VERSION ""

NS_ :

BS_:

BU_: XXX BCM CEM FSM PSCM SAS

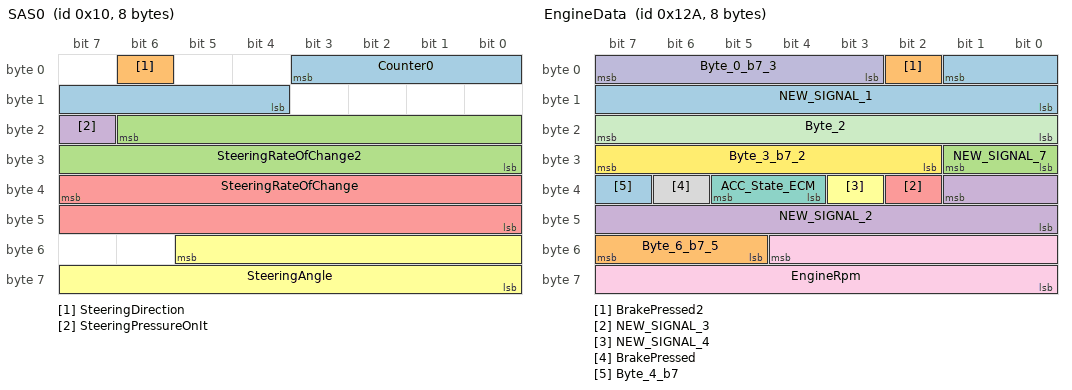
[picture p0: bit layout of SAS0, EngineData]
BO_ 16 SAS0: 8 SAS
 SG_ Counter0 : 3|8@0+ (1,0) [0|511] "" XXX
 SG_ SteeringDirection : 6|1@0+ (1,0) [0|1] "" XXX
 SG_ SteeringRateOfChange2 : 22|15@0+ (1,0) [0|32767] "" XXX
 SG_ SteeringPressureOnIt : 23|1@0+ (1,0) [0|1] "" XXX
 SG_ SteeringRateOfChange : 39|16@0+ (1,-32768) [0|65535] "" XXX
 SG_ SteeringAngle : 53|14@0+ (0.0445,0) [0|65535] "degrees" XXX

BO_ 32 AccPedal: 8 XXX
 SG_ AccPedal : 17|10@0+ (0.1,0) [0|102.3] "%" XXX

BO_ 81 FSM0: 8 FSM
 SG_ ACC_FrontCar : 16|1@0+ (1,0) [0|1] "" XXX
 SG_ ACC_Available : 17|1@0+ (1,0) [0|7] "" XXX
 SG_ ACC_Enabled : 18|1@0+ (1,0) [0|1] "" XXX
 SG_ ACC_BrakeAlert : 27|1@0+ (1,0) [0|1] "" XXX
 SG_ Byte_0 : 7|8@0+ (1,0) [0|255] "" XXX
 SG_ Byte_1 : 15|8@0+ (1,0) [0|255] "" XXX
 SG_ Byte_2_b7_3 : 23|5@0+ (1,0) [0|31] "" XXX
 SG_ ACC_AbortCode : 31|8@0+ (1,0) [0|255] "" XXX
 SG_ Byte_4 : 39|8@0+ (1,0) [0|255] "" XXX
 SG_ Byte_5 : 47|8@0+ (1,0) [0|255] "" XXX
 SG_ Byte_6 : 55|8@0+ (1,0) [0|255] "" XXX
 SG_ Byte_7 : 63|8@0+ (1,0) [0|255] "" XXX

BO_ 99 GearSelector: 8 XXX
 SG_ GearLever : 54|2@0+ (1,0) [0|3] "" XXX

BO_ 112 ButtonPanel: 8 XXX
 SG_ Console_Button_Pressed : 18|1@0+ (1,0) [0|1] "" XXX

BO_ 277 NEW_MSG_7: 8 XXX
 SG_ NEW_SIGNAL_1 : 39|16@0+ (1,0) [0|65535] "" XXX

BO_ 295 CCButtons: 8 CEM
 SG_ ACCMinusBtnInv : 32|1@0+ (1,0) [0|1] "" XXX
 SG_ TimeGapIncreaseBtnInv : 33|1@0+ (1,0) [0|1] "" XXX
 SG_ TimeGapDecreaseBtnInv : 34|1@0+ (1,0) [0|1] "" XXX
 SG_ ACCOnOffBtnInv : 43|1@0+ (1,0) [0|1] "" XXX
 SG_ ACCResumeBtnInv : 45|1@0+ (1,0) [0|1] "" XXX
 SG_ ACCSetBtnInv : 47|1@0+ (1,0) [0|1] "" XXX
 SG_ ACCMinusBtn : 48|1@0+ (1,0) [0|1] "" XXX
 SG_ TimeGapIncreaseBtn : 49|1@0+ (1,0) [0|1] "" XXX
 SG_ TimeGapDecreaseBtn : 50|1@0+ (1,0) [0|1] "" XXX
 SG_ ACCOnOffBtn : 59|1@0+ (1,0) [0|1] "" XXX
 SG_ ACCResumeBtn : 61|1@0+ (1,0) [0|1] "" XXX
 SG_ ACCSetBtn : 63|1@0+ (1,0) [0|1] "" XXX
 SG_ Byte_0 : 7|8@0+ (1,0) [0|255] "" XXX
 SG_ Byte_1 : 15|8@0+ (1,0) [0|255] "" XXX
 SG_ Byte_2_b7_3 : 23|5@0+ (1,0) [0|31] "" XXX
 SG_ LKA_State : 18|1@0+ (1,0) [0|1] "" XXX
 SG_ Byte_2_b1_0 : 17|2@0+ (1,0) [0|3] "" XXX
 SG_ Byte_3 : 31|8@0+ (1,0) [0|255] "" XXX
 SG_ Byte_4_b7_3 : 39|5@0+ (1,0) [0|31] "" XXX
 SG_ Byte_5_b6 : 46|1@0+ (1,0) [0|1] "" XXX
 SG_ Byte_5_b4 : 44|1@0+ (1,0) [0|1] "" XXX
 SG_ Byte_5_b2_0 : 42|3@0+ (1,0) [0|7] "" XXX
 SG_ Byte_6_b7_3 : 55|5@0+ (1,0) [0|31] "" XXX
 SG_ Byte_7_b6 : 62|1@0+ (1,0) [0|1] "" XXX
 SG_ Byte_7_b4 : 60|1@0+ (1,0) [0|1] "" XXX
 SG_ Byte_7_b2_0 : 58|3@0+ (1,0) [0|7] "" XXX

BO_ 298 EngineData: 8 XXX
 SG_ NEW_SIGNAL_1 : 1|10@0+ (1,0) [0|1023] "" XXX
 SG_ BrakePressed2 : 2|1@0+ (1,0) [0|1] "" XXX
 SG_ NEW_SIGNAL_7 : 25|2@0+ (1,0) [0|3] "" XXX
 SG_ NEW_SIGNAL_2 : 33|10@0- (1,0) [0|7] "" XXX
 SG_ NEW_SIGNAL_3 : 34|1@0+ (1,0) [0|1] "" XXX
 SG_ NEW_SIGNAL_4 : 35|1@0+ (1,0) [0|1] "" XXX
 SG_ ACC_State_ECM : 37|2@0+ (1,0) [0|3] "" XXX
 SG_ BrakePressed : 38|1@0+ (1,0) [0|1] "" XXX
 SG_ EngineRpm : 52|13@0+ (1,0) [0|8000] "" XXX
 SG_ Byte_0_b7_3 : 7|5@0+ (1,0) [0|31] "" XXX
 SG_ Byte_2 : 23|8@0+ (1,0) [0|255] "" XXX
 SG_ Byte_3_b7_2 : 31|6@0+ (1,0) [0|63] "" XXX
 SG_ Byte_4_b7 : 39|1@0+ (1,0) [0|1] "" XXX
 SG_ Byte_6_b7_5 : 55|3@0+ (1,0) [0|7] "" XXX

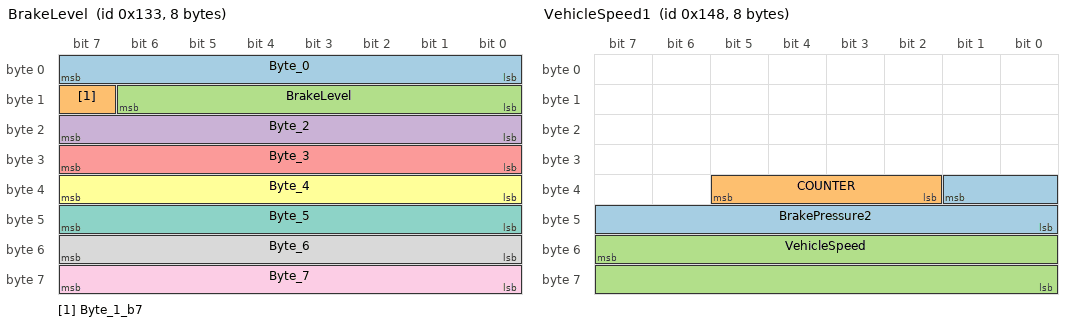
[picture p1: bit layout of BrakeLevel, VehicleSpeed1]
BO_ 307 BrakeLevel: 8 XXX
 SG_ Byte_0 : 7|8@0+ (1,0) [0|255] "" XXX
 SG_ Byte_1_b7 : 15|1@0+ (1,0) [0|1] "" XXX
 SG_ BrakeLevel : 14|7@0+ (1,0) [0|127] "" XXX
 SG_ Byte_2 : 23|8@0+ (1,0) [0|255] "" XXX
 SG_ Byte_3 : 31|8@0+ (1,0) [0|255] "" XXX
 SG_ Byte_4 : 39|8@0+ (1,0) [0|255] "" XXX
 SG_ Byte_5 : 47|8@0+ (1,0) [0|255] "" XXX
 SG_ Byte_6 : 55|8@0+ (1,0) [0|255] "" XXX
 SG_ Byte_7 : 63|8@0+ (1,0) [0|255] "" XXX

BO_ 328 VehicleSpeed1: 8 XXX
 SG_ BrakePressure2 : 33|10@0+ (1,0) [0|63] "" XXX
 SG_ COUNTER : 37|4@0+ (1,0) [0|15] "" XXX
 SG_ VehicleSpeed : 55|16@0+ (0.01,0) [0|65535] "" XXX

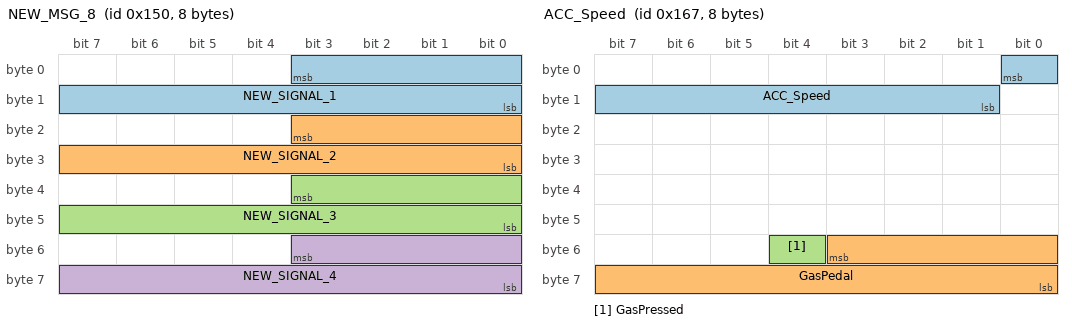
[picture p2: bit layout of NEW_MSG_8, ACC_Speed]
BO_ 336 NEW_MSG_8: 8 XXX
 SG_ NEW_SIGNAL_1 : 3|12@0+ (1,0) [0|4095] "" XXX
 SG_ NEW_SIGNAL_2 : 19|12@0+ (1,0) [0|4095] "" XXX
 SG_ NEW_SIGNAL_3 : 35|12@0+ (1,0) [0|4095] "" XXX
 SG_ NEW_SIGNAL_4 : 51|12@0+ (1,0) [0|4095] "" XXX

BO_ 359 ACC_Speed: 8 XXX
 SG_ ACC_Speed : 0|8@0+ (1,0) [0|255] "km/h" XXX
 SG_ GasPedal : 51|12@0- (1,0) [0|255] "" XXX
 SG_ GasPressed : 52|1@0+ (1,0) [0|1] "" XXX

BO_ 384 Accessories_02: 8 XXX
 SG_ Park_Assist_State : 42|1@0+ (1,0) [0|1] "" XXX
 SG_ StartStop_Inv : 44|1@0+ (1,0) [0|1] "" XXX

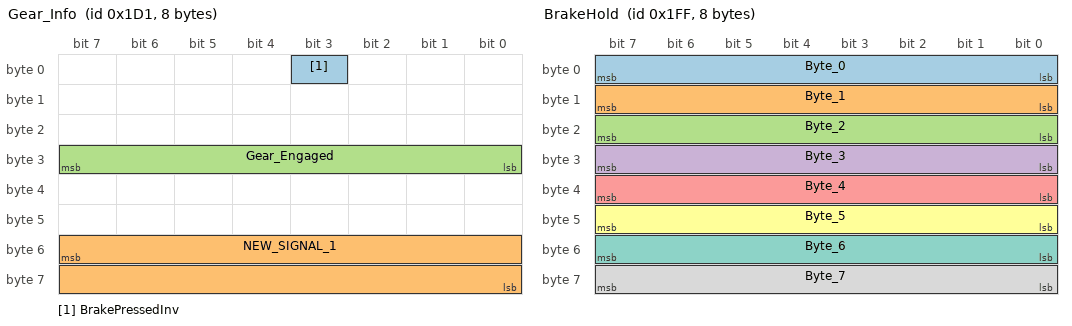
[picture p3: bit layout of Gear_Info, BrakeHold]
BO_ 465 Gear_Info: 8 XXX
 SG_ BrakePressedInv : 3|1@0+ (1,0) [0|1] "" XXX
 SG_ NEW_SIGNAL_1 : 55|16@0+ (1,0) [0|4095] "" XXX
 SG_ Gear_Engaged : 31|8@0+ (1,0) [0|255] "" XXX

BO_ 511 BrakeHold: 8 XXX
 SG_ Byte_0 : 7|8@0+ (1,0) [0|255] "" XXX
 SG_ Byte_1 : 15|8@0+ (1,0) [0|255] "" XXX
 SG_ Byte_2 : 23|8@0+ (1,0) [0|255] "" XXX
 SG_ Byte_3 : 31|8@0+ (1,0) [0|255] "" XXX
 SG_ Byte_4 : 39|8@0+ (1,0) [0|255] "" XXX
 SG_ Byte_5 : 47|8@0+ (1,0) [0|255] "" XXX
 SG_ Byte_6 : 55|8@0+ (1,0) [0|255] "" XXX
 SG_ Byte_7 : 63|8@0+ (1,0) [0|255] "" XXX

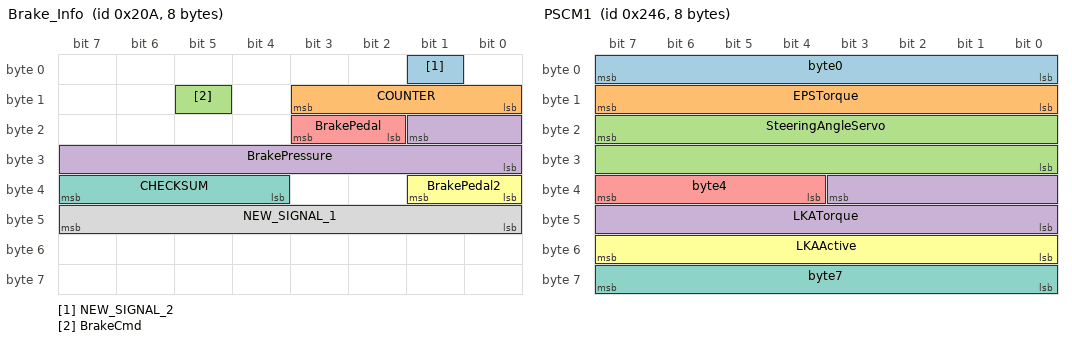
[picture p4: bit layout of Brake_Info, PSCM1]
BO_ 522 Brake_Info: 8 XXX
 SG_ NEW_SIGNAL_2 : 1|1@0+ (1,0) [0|1] "" XXX
 SG_ COUNTER : 11|4@0+ (1,0) [0|15] "" XXX
 SG_ BrakeCmd : 13|1@0+ (1,0) [0|1] "" XXX
 SG_ BrakePressure : 17|10@0+ (1,0) [0|255] "" XXX
 SG_ BrakePedal : 19|2@0+ (1,0) [0|3] "" XXX
 SG_ BrakePedal2 : 33|2@0+ (1,0) [0|3] "" XXX
 SG_ CHECKSUM : 39|4@0+ (1,0) [0|15] "" XXX
 SG_ NEW_SIGNAL_1 : 47|8@0+ (1,0) [0|255] "" XXX

BO_ 544 wheelspeed1: 8 BCM
 SG_ WhlSpdRR : 39|16@0+ (0.01,-327.68) [0|65535] "" XXX
 SG_ WhlSpdLR : 55|16@0+ (0.01,-327.68) [0|65535] "" XXX
 SG_ Byte_0_b7 : 7|1@0+ (1,0) [0|1] "" XXX
 SG_ StandstillHold : 6|1@0+ (1,0) [0|1] "" XXX
 SG_ Byte_0_b5_0 : 5|6@0+ (1,0) [0|63] "" XXX
 SG_ Byte_1 : 15|8@0+ (1,0) [0|255] "" XXX
 SG_ Byte_2_b7_3 : 23|5@0+ (1,0) [0|31] "" XXX
 SG_ BrakeReqActive : 18|1@0+ (1,0) [0|1] "" XXX
 SG_ Byte_2_b1 : 17|1@0+ (1,0) [0|1] "" XXX
 SG_ ACC_BrakeApplied : 16|1@0+ (1,0) [0|1] "" XXX
 SG_ Byte_3 : 31|8@0+ (1,0) [0|255] "" XXX
 SG_ Byte_4 : 39|8@0+ (1,0) [0|255] "" XXX
 SG_ Byte_5 : 47|8@0+ (1,0) [0|255] "" XXX
 SG_ Byte_6 : 55|8@0+ (1,0) [0|255] "" XXX
 SG_ Byte_7 : 63|8@0+ (1,0) [0|255] "" XXX

BO_ 565 wheelspeed0: 8 BCM
 SG_ WhlSpdRF : 39|16@0+ (0.01,-327.68) [0|65535] "" XXX
 SG_ WhlSpdLF : 55|16@0+ (0.01,-327.68) [0|65535] "" XXX

BO_ 582 PSCM1: 8 PSCM
 SG_ byte0 : 7|8@0+ (1,0) [0|255] "" XXX
 SG_ EPSTorque : 15|8@0+ (1,0) [0|255] "" XXX
 SG_ SteeringAngleServo : 23|16@0+ (0.0447,-1465) [0|65535] "deg" XXX
 SG_ LKATorque : 35|12@0+ (1,-2000) [0|65535] "" XXX
 SG_ byte4 : 39|4@0+ (1,0) [0|15] "" XXX
 SG_ LKAActive : 55|8@0+ (1,0) [0|255] "" XXX
 SG_ byte7 : 63|8@0+ (1,0) [0|255] "" XXX

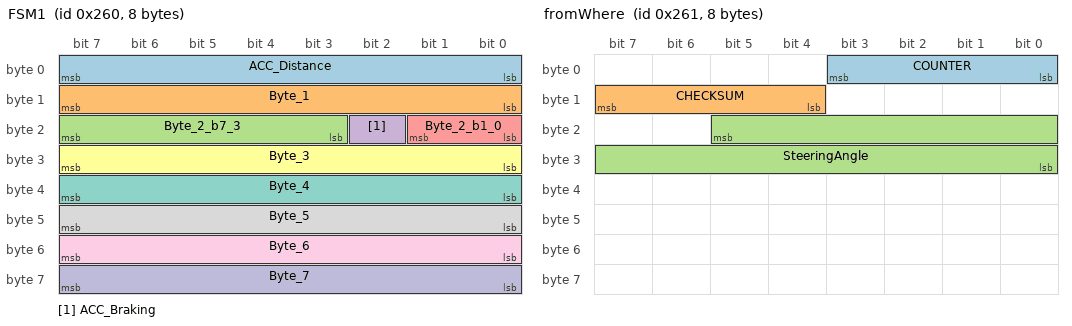
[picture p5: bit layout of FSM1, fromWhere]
BO_ 608 FSM1: 8 FSM
 SG_ ACC_Distance : 7|8@0+ (1,0) [0|255] "" XXX
 SG_ Byte_1 : 15|8@0+ (1,0) [0|255] "" XXX
 SG_ Byte_2_b7_3 : 23|5@0+ (1,0) [0|31] "" XXX
 SG_ ACC_Braking : 18|1@0+ (1,0) [0|1] "" XXX
 SG_ Byte_2_b1_0 : 17|2@0+ (1,0) [0|3] "" XXX
 SG_ Byte_3 : 31|8@0+ (1,0) [0|255] "" XXX
 SG_ Byte_4 : 39|8@0+ (1,0) [0|255] "" XXX
 SG_ Byte_5 : 47|8@0+ (1,0) [0|255] "" XXX
 SG_ Byte_6 : 55|8@0+ (1,0) [0|255] "" XXX
 SG_ Byte_7 : 63|8@0+ (1,0) [0|255] "" XXX

BO_ 609 fromWhere: 8 XXX
 SG_ COUNTER : 3|4@0+ (1,0) [0|15] "" XXX
 SG_ CHECKSUM : 15|4@0+ (1,0) [0|15] "" XXX
 SG_ SteeringAngle : 21|14@0+ (0.1,-1021) [0|65535] "deg" XXX

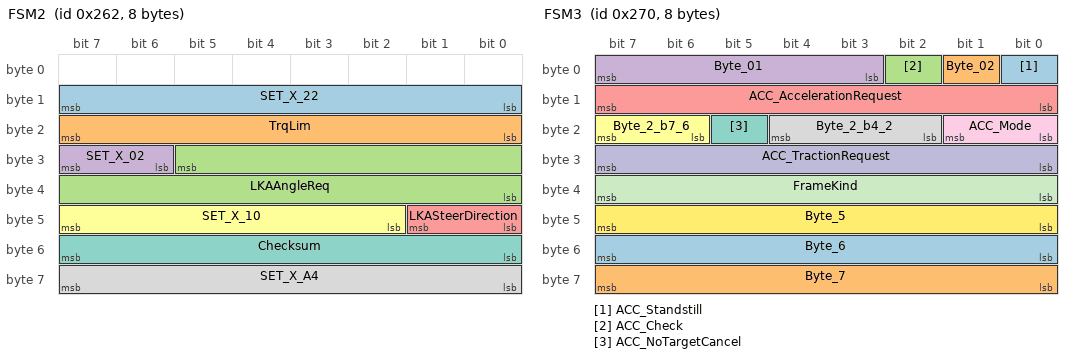
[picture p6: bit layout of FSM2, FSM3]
BO_ 610 FSM2: 8 FSM
 SG_ SET_X_22 : 15|8@0+ (1,0) [0|255] "" XXX
 SG_ TrqLim : 23|8@0+ (1,-128) [0|255] "" PSCM
 SG_ LKAAngleReq : 29|14@0+ (0.04,-327.68) [0|16383] "" PSCM
 SG_ SET_X_02 : 31|2@0+ (1,0) [0|3] "" XXX
 SG_ LKASteerDirection : 41|2@0+ (1,0) [0|3] "" PSCM
 SG_ SET_X_10 : 47|6@0+ (1,0) [0|63] "" XXX
 SG_ Checksum : 55|8@0+ (1,0) [0|255] "" PSCM
 SG_ SET_X_A4 : 63|8@0+ (1,0) [0|255] "" XXX

BO_ 612 Accessories_03: 8 XXX
 SG_ Park_Assist_Button : 60|1@0+ (1,0) [0|1] "" XXX
 SG_ RearParkWarning_Button : 58|1@0+ (1,0) [0|1] "" XXX

BO_ 624 FSM3: 8 FSM
 SG_ ACC_Standstill : 0|1@0+ (1,0) [0|1] "" XXX
 SG_ Byte_02 : 1|1@0+ (1,0) [0|1] "" XXX
 SG_ ACC_Check : 2|1@0+ (1,0) [0|1] "" XXX
 SG_ Byte_01 : 7|5@0+ (1,0) [0|31] "" XXX
 SG_ ACC_AccelerationRequest : 15|8@0+ (0.04,-5.04) [0|255] "" XXX
 SG_ Byte_2_b7_6 : 23|2@0+ (1,0) [0|3] "" XXX
 SG_ ACC_NoTargetCancel : 21|1@0+ (1,0) [0|1] "" XXX
 SG_ Byte_2_b4_2 : 20|3@0+ (1,0) [0|7] "" XXX
 SG_ ACC_Mode : 17|2@0+ (1,0) [0|3] "" XXX
 SG_ ACC_TractionRequest : 31|8@0+ (1,0) [0|255] "" XXX
 SG_ FrameKind : 39|8@0+ (1,0) [0|255] "" XXX
 SG_ Byte_5 : 47|8@0+ (1,0) [0|255] "" XXX
 SG_ Byte_6 : 55|8@0+ (1,0) [0|255] "" XXX
 SG_ Byte_7 : 63|8@0+ (1,0) [0|255] "" XXX

BO_ 648 BrakePedal: 8 XXX
 SG_ Counter : 0|3@1+ (1,0) [0|6] "" XXX
 SG_ BrakePressure : 17|10@0+ (1,0) [0|1023] "" XXX

BO_ 750 HandBrake: 8 XXX
 SG_ Hand_Brake_Button : 33|2@0+ (1,0) [0|3] "" XXX
 SG_ Hand_Brake_State : 44|4@0+ (1,0) [0|15] "" XXX

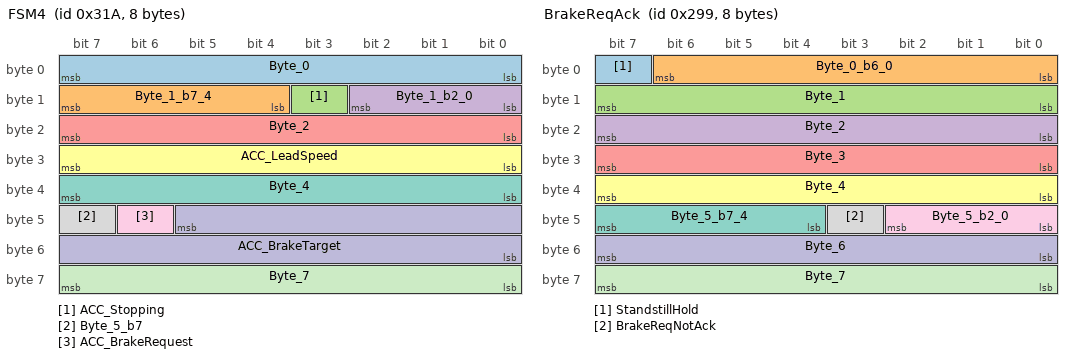
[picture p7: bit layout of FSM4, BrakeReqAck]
BO_ 794 FSM4: 8 FSM
 SG_ Byte_0 : 7|8@0+ (1,0) [0|255] "" XXX
 SG_ Byte_1_b7_4 : 15|4@0+ (1,0) [0|15] "" XXX
 SG_ ACC_Stopping : 11|1@0+ (1,0) [0|1] "" XXX
 SG_ Byte_1_b2_0 : 10|3@0+ (1,0) [0|7] "" XXX
 SG_ Byte_2 : 23|8@0+ (1,0) [0|255] "" XXX
 SG_ ACC_LeadSpeed : 31|8@0+ (1,0) [0|255] "" XXX
 SG_ Byte_4 : 39|8@0+ (1,0) [0|255] "" XXX
 SG_ Byte_5_b7 : 47|1@0+ (1,0) [0|1] "" XXX
 SG_ ACC_BrakeRequest : 46|1@0+ (1,0) [0|1] "" XXX
 SG_ ACC_BrakeTarget : 45|14@0+ (1,0) [0|16383] "" XXX
 SG_ Byte_7 : 63|8@0+ (1,0) [0|255] "" XXX

BO_ 665 BrakeReqAck: 8 XXX
 SG_ StandstillHold : 7|1@0+ (1,0) [0|1] "" XXX
 SG_ Byte_0_b6_0 : 6|7@0+ (1,0) [0|127] "" XXX
 SG_ Byte_1 : 15|8@0+ (1,0) [0|255] "" XXX
 SG_ Byte_2 : 23|8@0+ (1,0) [0|255] "" XXX
 SG_ Byte_3 : 31|8@0+ (1,0) [0|255] "" XXX
 SG_ Byte_4 : 39|8@0+ (1,0) [0|255] "" XXX
 SG_ Byte_5_b7_4 : 47|4@0+ (1,0) [0|15] "" XXX
 SG_ BrakeReqNotAck : 43|1@0+ (1,0) [0|1] "" XXX
 SG_ Byte_5_b2_0 : 42|3@0+ (1,0) [0|7] "" XXX
 SG_ Byte_6 : 55|8@0+ (1,0) [0|255] "" XXX
 SG_ Byte_7 : 63|8@0+ (1,0) [0|255] "" XXX

BO_ 706 RearParkWarning_Status: 8 XXX
 SG_ RearParkWarning_State : 35|1@0+ (1,0) [0|1] "" XXX

BO_ 807 ParkAssist_Status: 8 XXX
 SG_ Park_Assist_Off : 40|1@0+ (1,0) [0|1] "" XXX

BO_ 802 StartStop: 8 XXX
 SG_ StartStop : 8|1@0+ (1,0) [0|1] "" XXX

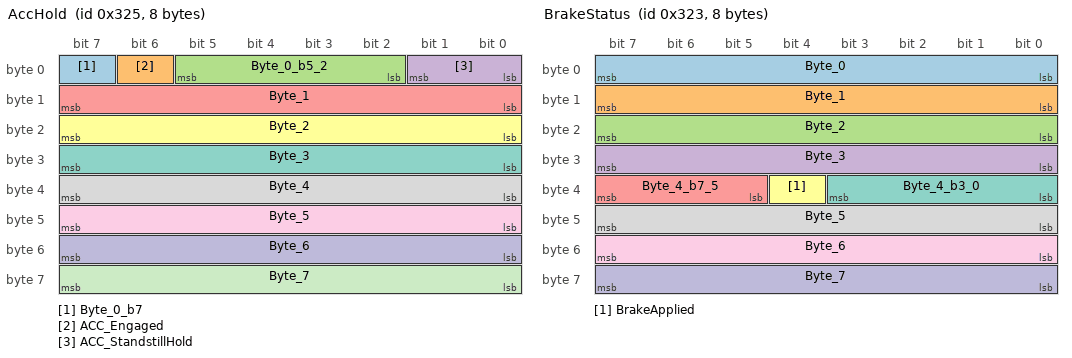
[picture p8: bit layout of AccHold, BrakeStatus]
BO_ 805 AccHold: 8 XXX
 SG_ Byte_0_b7 : 7|1@0+ (1,0) [0|1] "" XXX
 SG_ ACC_Engaged : 6|1@0+ (1,0) [0|1] "" XXX
 SG_ Byte_0_b5_2 : 5|4@0+ (1,0) [0|15] "" XXX
 SG_ ACC_StandstillHold : 1|2@0+ (1,0) [0|3] "" XXX
 SG_ Byte_1 : 15|8@0+ (1,0) [0|255] "" XXX
 SG_ Byte_2 : 23|8@0+ (1,0) [0|255] "" XXX
 SG_ Byte_3 : 31|8@0+ (1,0) [0|255] "" XXX
 SG_ Byte_4 : 39|8@0+ (1,0) [0|255] "" XXX
 SG_ Byte_5 : 47|8@0+ (1,0) [0|255] "" XXX
 SG_ Byte_6 : 55|8@0+ (1,0) [0|255] "" XXX
 SG_ Byte_7 : 63|8@0+ (1,0) [0|255] "" XXX

BO_ 803 BrakeStatus: 8 XXX
 SG_ Byte_0 : 7|8@0+ (1,0) [0|255] "" XXX
 SG_ Byte_1 : 15|8@0+ (1,0) [0|255] "" XXX
 SG_ Byte_2 : 23|8@0+ (1,0) [0|255] "" XXX
 SG_ Byte_3 : 31|8@0+ (1,0) [0|255] "" XXX
 SG_ Byte_4_b7_5 : 39|3@0+ (1,0) [0|7] "" XXX
 SG_ BrakeApplied : 36|1@0+ (1,0) [0|1] "" XXX
 SG_ Byte_4_b3_0 : 35|4@0+ (1,0) [0|15] "" XXX
 SG_ Byte_5 : 47|8@0+ (1,0) [0|255] "" XXX
 SG_ Byte_6 : 55|8@0+ (1,0) [0|255] "" XXX
 SG_ Byte_7 : 63|8@0+ (1,0) [0|255] "" XXX

BO_ 923 Accessories_01: 8 XXX
 SG_ NEW_SIGNAL_1 : 15|16@0+ (1,0) [0|65535] "" XXX
 SG_ Wipers : 38|2@0+ (1,0) [0|3] "" XXX

BO_ 1006 Doors: 8 XXX
 SG_ DriverDoorClosed : 8|1@0+ (1,0) [0|1] "" XXX
 SG_ PassengerDoorClosed : 9|1@0+ (1,0) [0|1] "" XXX

BO_ 1021 FSM5: 8 FSM
 SG_ TSR_Speed : 25|4@1+ (10,0) [0|15] "km/h" XXX

BO_ 1024 NEW_MSG_400: 8 XXX
 SG_ NEW_SIGNAL_1 : 25|8@0+ (1,0) [0|255] "" XXX

BO_ 1039 MiscCarInfo: 8 XXX
 SG_ TurnSignal : 33|2@0+ (1,0) [0|3] "" XXX

BO_ 1174 Lights: 8 XXX
 SG_ High_Beam : 23|1@0+ (1,0) [0|1] "" XXX

BO_ 1279 PSCM3: 8 PSCM

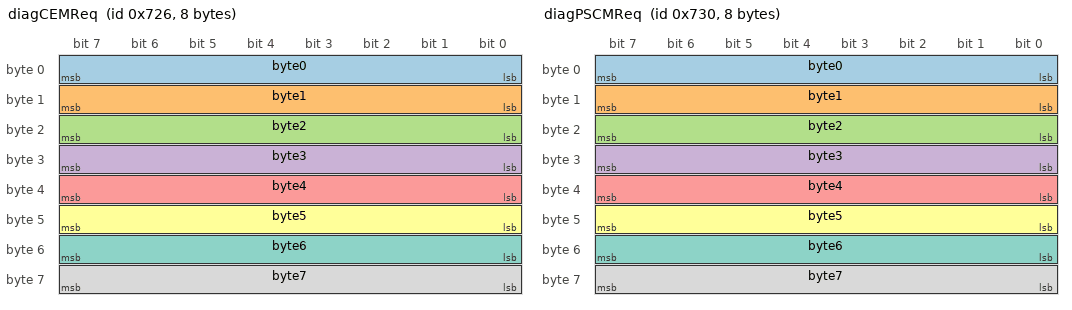
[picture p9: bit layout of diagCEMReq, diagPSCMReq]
BO_ 1830 diagCEMReq: 8 XXX
 SG_ byte0 : 7|8@0+ (1,0) [0|255] "" XXX
 SG_ byte1 : 15|8@0+ (1,0) [0|255] "" XXX
 SG_ byte2 : 23|8@0+ (1,0) [0|255] "" XXX
 SG_ byte3 : 31|8@0+ (1,0) [0|255] "" XXX
 SG_ byte4 : 39|8@0+ (1,0) [0|255] "" XXX
 SG_ byte5 : 47|8@0+ (1,0) [0|255] "" XXX
 SG_ byte6 : 55|8@0+ (1,0) [0|255] "" XXX
 SG_ byte7 : 63|8@0+ (1,0) [0|255] "" XXX

BO_ 1838 diagCEMResp: 8 XXX
 SG_ byte03 : 7|32@0+ (1,0) [0|4294967295] "" XXX
 SG_ byte47 : 39|32@0+ (1,0) [0|4294967295] "" XXX

BO_ 1840 diagPSCMReq: 8 XXX
 SG_ byte0 : 7|8@0+ (1,0) [0|255] "" XXX
 SG_ byte1 : 15|8@0+ (1,0) [0|255] "" XXX
 SG_ byte2 : 23|8@0+ (1,0) [0|255] "" XXX
 SG_ byte3 : 31|8@0+ (1,0) [0|255] "" XXX
 SG_ byte4 : 39|8@0+ (1,0) [0|255] "" XXX
 SG_ byte5 : 47|8@0+ (1,0) [0|255] "" XXX
 SG_ byte6 : 55|8@0+ (1,0) [0|255] "" XXX
 SG_ byte7 : 63|8@0+ (1,0) [0|255] "" XXX

BO_ 1848 diagPSCMResp: 8 XXX
 SG_ byte03 : 7|32@0+ (1,0) [0|4294967295] "" XXX
 SG_ byte47 : 39|32@0+ (1,0) [0|4294967295] "" XXX

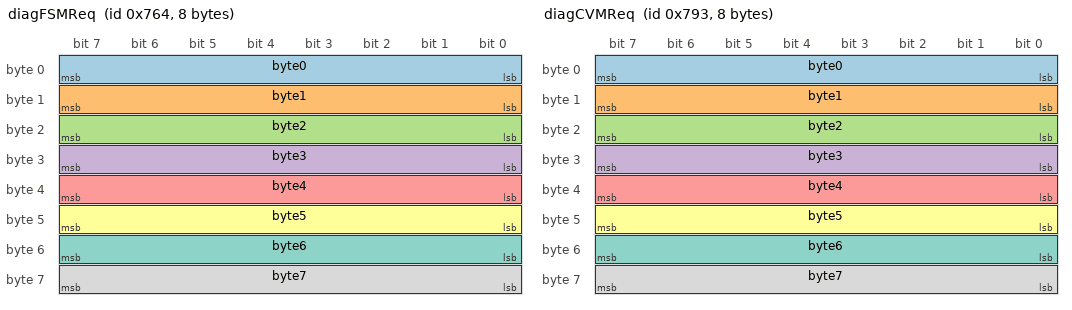
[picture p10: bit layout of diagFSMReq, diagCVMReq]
BO_ 1892 diagFSMReq: 8 XXX
 SG_ byte0 : 7|8@0+ (1,0) [0|255] "" XXX
 SG_ byte1 : 15|8@0+ (1,0) [0|255] "" XXX
 SG_ byte2 : 23|8@0+ (1,0) [0|255] "" XXX
 SG_ byte3 : 31|8@0+ (1,0) [0|255] "" XXX
 SG_ byte4 : 39|8@0+ (1,0) [0|255] "" XXX
 SG_ byte5 : 47|8@0+ (1,0) [0|255] "" XXX
 SG_ byte6 : 55|8@0+ (1,0) [0|255] "" XXX
 SG_ byte7 : 63|8@0+ (1,0) [0|255] "" XXX

BO_ 1900 diagFSMResp: 8 XXX
 SG_ byte03 : 7|32@0+ (1,0) [0|4294967295] "" XXX
 SG_ byte47 : 39|32@0+ (1,0) [0|4294967295] "" XXX

BO_ 1939 diagCVMReq: 8 XXX
 SG_ byte0 : 7|8@0+ (1,0) [0|255] "" XXX
 SG_ byte1 : 15|8@0+ (1,0) [0|255] "" XXX
 SG_ byte2 : 23|8@0+ (1,0) [0|255] "" XXX
 SG_ byte3 : 31|8@0+ (1,0) [0|255] "" XXX
 SG_ byte4 : 39|8@0+ (1,0) [0|255] "" XXX
 SG_ byte5 : 47|8@0+ (1,0) [0|255] "" XXX
 SG_ byte6 : 55|8@0+ (1,0) [0|255] "" XXX
 SG_ byte7 : 63|8@0+ (1,0) [0|255] "" XXX

BO_ 1947 diagCVMResp: 8 XXX
 SG_ byte03 : 7|32@0+ (1,0) [0|4294967295] "" XXX
 SG_ byte47 : 39|32@0+ (1,0) [0|4294967295] "" XXX

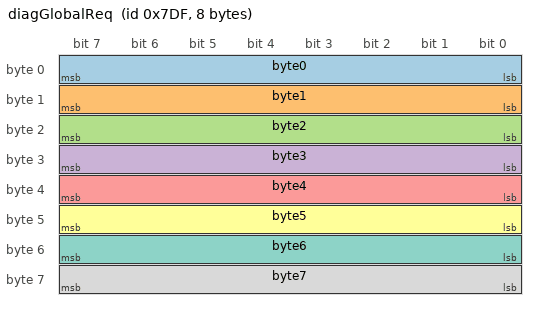
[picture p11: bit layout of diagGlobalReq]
BO_ 2015 diagGlobalReq: 8 XXX
 SG_ byte0 : 7|8@0+ (1,0) [0|255] "" XXX
 SG_ byte1 : 15|8@0+ (1,0) [0|255] "" XXX
 SG_ byte2 : 23|8@0+ (1,0) [0|255] "" XXX
 SG_ byte3 : 31|8@0+ (1,0) [0|255] "" XXX
 SG_ byte4 : 39|8@0+ (1,0) [0|255] "" XXX
 SG_ byte5 : 47|8@0+ (1,0) [0|255] "" XXX
 SG_ byte6 : 55|8@0+ (1,0) [0|255] "" XXX
 SG_ byte7 : 63|8@0+ (1,0) [0|255] "" XXX

CM_ SG_ 112 Console_Button_Pressed "Any console button (LKA, rear park warning, park assist, start/stop)";
CM_ SG_ 81 ACC_AbortCode "0x10 generic abort, 0x04 latched fault";
CM_ SG_ 608 ACC_Braking "Set while ACC brakes";
CM_ SG_ 624 ACC_NoTargetCancel "Camera cancels: slow with no target";
CM_ SG_ 624 ACC_Mode "0 brake, 1 coast, 2 drive";
CM_ SG_ 624 ACC_TractionRequest "Signed in coast (negative = engine drag), unsigned in drive";
CM_ SG_ 794 Byte_5_b7 "Always 1";
CM_ SG_ 794 ACC_BrakeRequest "Hydraulic brake requested";
CM_ SG_ 794 ACC_BrakeTarget "Brake target, lower = more braking";
CM_ SG_ 307 BrakeLevel "Brake level seen by the camera";
CM_ SG_ 544 BrakeReqActive "Brake request active, seen by the camera";
CM_ SG_ 665 BrakeReqNotAck "Active low: 0 = car acknowledges the camera brake request";
CM_ SG_ 803 BrakeApplied "Brake applied, seen by the camera";
CM_ SG_ 805 Byte_0 "0xC4 ACC engaged moving, 0x84 not, 0x87 ACC standstill hold (routes 807, 881)";
CM_ SG_ 298 Byte_2 "bit5 set while ACC engaged and moving (E7), clear at standstill or standby (C7)";
CM_ SG_ 511 Byte_0 "0x70 -> 0xD0 ~4.4 s into a stop: brake hold state change (routes 807, 87b)";
CM_ SG_ 16 SteeringDirection "0 = CCW, 1=CW (turning left or right of center)";
CM_ SG_ 16 SteeringRateOfChange "Rate of change? Torque?";
CM_ SG_ 81 ACC_Available "0=Acc Unavailable, 1=???, 2=Acc Ready, 3,4=???, 6= Acc Active, 7=Acc active tracking object (probably)";
CM_ SG_ 295 ACCMinusBtnInv "Active zero when button pressed.";
CM_ SG_ 295 TimeGapIncreaseBtnInv "Active zero when button pressed.";
CM_ SG_ 295 TimeGapDecreaseBtnInv "Active zero when button pressed.";
CM_ SG_ 295 ACCOnOffBtnInv "Active zero when button pressed.";
CM_ SG_ 295 ACCResumeBtnInv "Active zero when button pressed.";
CM_ SG_ 295 ACCSetBtnInv "Active zero when button pressed.";
CM_ SG_ 295 ACCMinusBtn "ACC Minus (-) button pressed";
CM_ SG_ 295 TimeGapIncreaseBtn "Increase the time gap on ACC";
CM_ SG_ 295 TimeGapDecreaseBtn "Decrease the time gap on ACC";
CM_ SG_ 295 ACCOnOffBtn "Cruise control on/off button pressed";
CM_ SG_ 295 ACCResumeBtn "ACC Resume button pressed";
CM_ SG_ 295 ACCSetBtn "Acc Set button (+) pressed";
CM_ SG_ 298 NEW_SIGNAL_4 "related to gas pedal";
CM_ SG_ 298 NEW_SIGNAL_5 "related to ACCStatus";
CM_ SG_ 298 NEW_SIGNAL_6 "went high at same time as ACCStatus >= 2";
CM_ SG_ 298 BrakePressed "driver";
CM_ SG_ 298 EngineRpm "Might be engine rpm. But behaves abit weird.";
CM_ SG_ 582 byte0 "0=CCW, 1=CW, bit 2,";
CM_ SG_ 582 EPSTorque "Some rate of change for steering wheel? Torque?";
CM_ SG_ 582 byte4 "High nibble";
CM_ SG_ 582 LKAActive "Bit 1, 1 When LKA Active, Bit 3, 1 When denying?";
CM_ SG_ 608 ACC_Distance "Seems to track distance, or speed of vehicle in front.";
CM_ SG_ 610 SET_X_22 "0x20 Heartbeat, VEgo <58kph = 0x03, VEgo >65kph = 0x04, 0x05";
CM_ SG_ 648 Counter "counts 0 to 6";
CM_ SG_ 1021 TSR_Speed "Traffic Sign Recognition speed";
CM_ SG_ 1039 TurnSignal "0 = Nothing, 1= Left, 3=Right";
VAL_ 522 BrakePedal 1 "Not Pressed" 2 "Pressed";
VAL_ 99 GearLever 0 "P" 1 "R" 2 "N" 3 "D";
VAL_ 465 Gear_Engaged 50 "None (P/N)" 216 "Forward" 44 "Reverse";
